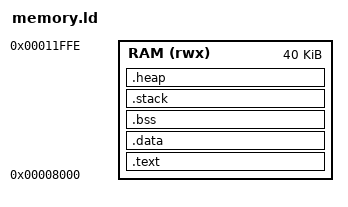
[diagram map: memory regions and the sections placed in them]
/* This was mostly generated by GPT */

OUTPUT_FORMAT("ihex")
ENTRY(_main)

MEMORY
{
    RAM (rwx) : ORIGIN = 0x8000, LENGTH = 0x9FFF
}

SECTIONS
{
    /* Code section (.text) */
    .text :
    {
        *(.text._main*)     /* Main code */
        *(.text*)     /* Main code */
        *(.vectors*)  /* Interrupt vectors (if any) */
        *(.rodata*)   /* Read-only data */
    } > RAM

    /* Initialized Data (.data) section */
    .data :
    {
        _sdata = .;   /* Start of .data */
        *(.data*)     /* Initialized variables */
        _edata = .;   /* End of .data */
    } > RAM AT > RAM

    /* Uninitialized Data (.bss) section */
    .bss :
    {
        _sbss = .;
        *(.bss*)      /* Zero-initialized variables */
        *(COMMON)     /* Common symbols */
        _ebss = .;
    } > RAM

    /* Stack grows downward from top of RAM (0xFFFF) */
    .stack (NOLOAD) :
    {
        _stack_top = 0xFFFF;
    } > RAM

    /* Heap starts after .bss and grows upwards */
    .heap :
    {
        _heap_start = .;
        _heap_end = _stack_top - 1024;  /* 1KB stack reserved */
    } > RAM
}

